# SG2000 register map
Vendor: Sophgo; File version: 1
Registers are 32-bit, read-write, reset 0x0 unless marked. A register's access mark holds for its fields unless they carry their own. Offsets are from the block's base; [hi:lo] are bit positions; lines under a group give offsets from that group; {n}, {i} and the like mark numbered series.

## UART0 — UART
Base 0x04140000
Same registers: UART1 0x04150000, UART2 0x04160000, UART3 0x04170000, UART4 0x041C0000, RTCSYS_UART 0x05022000
0x00 RBR_THR — Receive Buffer Register, Transmit Holding Register
  [7:0] RBR_THR — (R)Receive Buffer Register, Data byte received on the serial input port. (W)Transmit Holding Register, Data to be transmitted on the serial output port
0x00 DLL (alternate view of RBR_THR) — Divisor Latch Low byte Register
  [7:0] DLL — Lower 8 bits of a 16-bit Divisor Latch register that contains the baud rate divisor for the UART
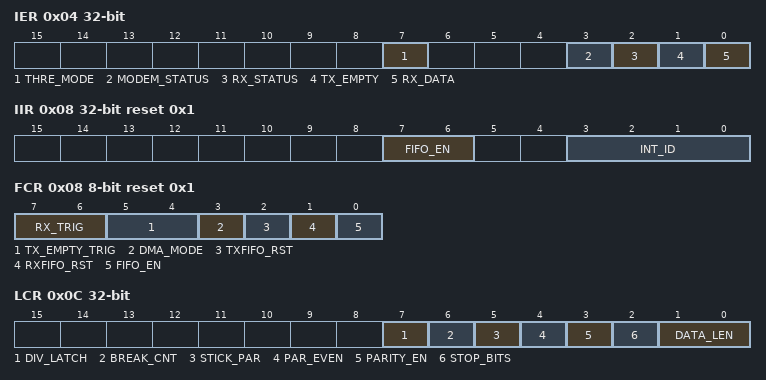
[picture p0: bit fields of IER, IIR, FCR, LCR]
0x04 IER — Interrupt Enable Register
  [7] THRE_MODE — Enable Programmable THRE Interrupt Mode
  [3] MODEM_STATUS — Enable Modem Status Interrupt
  [2] RX_STATUS — Enable Receiver Line Status Interrupt
  [1] TX_EMPTY — Enable Transmit Holding Register Empty Interrupt
  [0] RX_DATA — Enable Received Data Enable Interrupt
0x04 DLH (alternate view of IER) — Divisor Latch high byte Register
  [7:0] DLH — Upper 8-bits of a 16-bit Divisor Latch register that contains the baud rate divisor for the UART
0x08 IIR ro reset 0x1 — Interrupt Identification Register
  [7:6] FIFO_EN — FIFOs Enabled Status
    0=Disabled; 3=Enabled
  [3:0] INT_ID — Interrupt ID Status
    0=ModemStatus; 1=No interrupt pending; 2=THREmpty (Trasmit holding register empty); 4=DataAvailable (Received data available); 6=LineStatus (Receiver line status); 7=BusyDetect; 12=CharTimeout (Character Timeout)
0x08 FCR 8-bit wo reset 0x1 (alternate view of IIR) — FIFO Control Register
  [7:6] RX_TRIG — RCVR Trigger Level
    0=Char1 (1 character in FIFO); 1=Quarter (FIFO 1/4 full); 2=Half (FIFO 1/2 full); 3=FullMinus2 (FIFO 2 less than full)
  [5:4] TX_EMPTY_TRIG — TX Empty Trigger Level
    0=Empty (FIFO empty); 1=Chars2 (2 characters in FIFO); 2=Quarter (FIFO 1/4 full); 3=Half (FIFO 1/2 full)
  [3] DMA_MODE — DMA Mode Select
    0=Mode0 (Single DMA data transfers); 1=Mode1 (Multi DMA data transfers (continuous))
  [2] TXFIFO_RST — Transmit FIFO Reset
  [1] RXFIFO_RST — Receiver FIFO Reset
  [0] FIFO_EN — FIFO Enable
0x0C LCR — Line Control Register
  [7] DIV_LATCH — Divisor Latch Access Bit
  [6] BREAK_CNT — Break control bit
  [5] STICK_PAR — Stick parity
  [4] PAR_EVEN — Even parity select
  [3] PARITY_EN — Parity enable
  [2] STOP_BITS — Number of stop bits.
    0=One (One stop bit); 1=Two (Two stop bits if DATA_LEN is not 0, else 1.5 bits)
  [1:0] DATA_LEN — Data length selection
    0=Five data bits; 1=Six (Six data bits); 2=Seven data bits; 3=Eight data bits
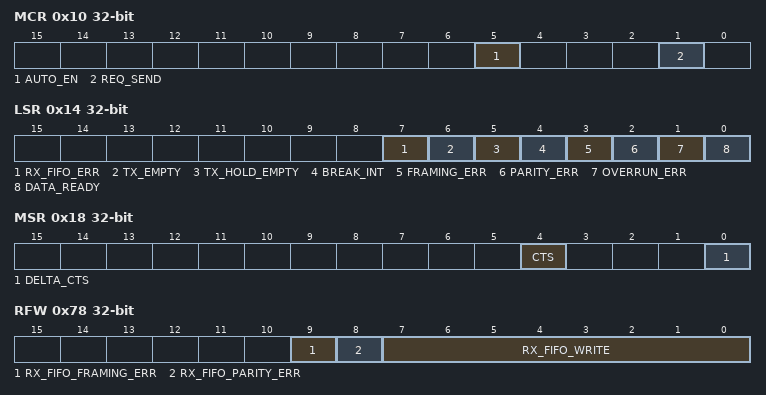
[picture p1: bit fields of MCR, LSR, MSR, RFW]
0x10 MCR access not given — Modem Control Register
  [5] AUTO_EN — Auto Flow Control Enable
  [1] REQ_SEND — Request to Send. This is used to directly control the Request to Send (rts_n) output
0x14 LSR ro reset not defined — Line Status Register
  [7] RX_FIFO_ERR — Receiver FIFO Error Bit
  [6] TX_EMPTY — Transmitter Empty Bit
  [5] TX_HOLD_EMPTY — Transmit Holding Register Empty Bit
  [4] BREAK_INT — Break Interrupt Bit
  [3] FRAMING_ERR — Framing Error Bit
  [2] PARITY_ERR — Parity Error Bit
  [1] OVERRUN_ERR — Overrun Error Bit
  [0] DATA_READY — Data Ready Bit
0x18 MSR ro reset not defined — Modem Status Register
  [4] CTS
  [0] DELTA_CTS — Delta Clear to Send.
0x20 LPDLL — Low Power Divisor Latch (Low) Register
  [7:0] ECO_DIV_LOW — Low Power Divisor Latch (Low byte) Register
0x24 LPDLH — Low Power Divisor Latch (High) Register
  [7:0] ECO_DIV_HIGH — Low Power Divisor Latch (High byte) Register
0x30 SRBR ro — Shadow Receive Buffer Register
  [7:0] RX_BUF
0x30 STHR wo reset not defined (alternate view of SRBR) — Shadow Transmit Buffer Register
  [7:0] TX_BUF — Shadow Transmit Holding Register
0x70 FAR — FIFO Access Register
  [0] FIFO_ACCESS — Used to enable a FIFO access mode for testing.
0x74 TFR — Transmit FIFO Read
  [7:0] TX_FIFO_READ — This bits are only valid when FIFO access mode is enabled.
0x78 RFW — Receive FIFO Write
  [9] RX_FIFO_FRAMING_ERR — Receive FIFO Framing Error
  [8] RX_FIFO_PARITY_ERR — Receive FIFO Parity Error
  [7:0] RX_FIFO_WRITE — Receive FIFO Write Data
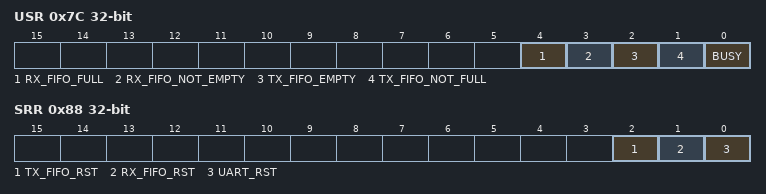
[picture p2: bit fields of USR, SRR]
0x7C USR ro reset not defined — UART Status Register
  [4] RX_FIFO_FULL — Receive FIFO Full
  [3] RX_FIFO_NOT_EMPTY — Receive FIFO Not EMPTY
  [2] TX_FIFO_EMPTY — Transmit FIFO Empty
  [1] TX_FIFO_NOT_FULL — Transmit FIFO Not Full
  [0] BUSY
0x80 TFL ro reset not defined — Transmit FIFO Level
  [5:0] TX_FIFO_LVL — This indicates the number of data entries in the transmit FIFO
0x84 RFL ro reset not defined — Receive FIFO Level
  [5:0] RX_FIFO_LVL — This indicates the number of data entries in the receive FIFO
0x88 SRR — Software Reset Register
  [2] TX_FIFO_RST — Transmitter FIFO Reset
  [1] RX_FIFO_RST — Receiver FIFO Reset
  [0] UART_RST — UART Reset
0x8C SRTS reset not defined — Shadow Request to Send
  [0] REQ_SEND — This is a shadow register for the RTS bit (MCR[1])
0x90 SBCR — Shadow Break Control Register
  [0] BREAK_CNT — This is a shadow register for the Break bit (LCR[6]).
0x94 SDMAM — Shadow DMA Mode
  [0] DMA_MODE — This is a shadow register for the DMA mode bit (FCR[3])
0x98 SFE — Shadow FIFO Enable
  [0] FIFO_EN — This is a shadow register for the FIFO enable bit (FCR[0])
0x9C SRT — Shadow RCVR Trigger
  [1:0] RX_TRIG — This is a shadow register for the RCVR trigger bits (FCR[7:6])
0xA0 STET — Shadow TX Empty Trigger
  [1:0] TX_EMPTY_TRIG — This is a shadow register for the TX empty trigger bits (FCR[5:4])
0xA4 HTX — Halt TX
  [0] HALT_TX — This register is used to halt transmissions for testing.
0xA8 DMASA — DMA Software Acknowledge
  [0] DMA_ACK — This register is used to perform a DMA software acknowledge if a transfer needs to be terminated due to an error condition.

## mailboxes
Base 0x01900000
{0x0+4i} cpu_mbox_en[{i}] (i=0..3) 8-bit — Mailbox Enable Bits
{0x10+0x10*i} cpu_mbox_int[{i}] (i=0..3) group — Interrupts Registers
  0x00 int_clr 8-bit — Interrupt Clear
  0x04 int_mask 8-bit — Interrupt Mask
  0x08 int_int 8-bit — Interrupt Status
  0x0C int_raw 8-bit — Interrupt Raw
0x60 mbox_set 8-bit
0x64 mbox_status 8-bit
{0x70+4i} cpu_mbox_status[{i}] (i=0..3) 8-bit
{0xC0+4i} spinlock[{i}] (i=0..7)
{0x400+4i} context[{i}] (i=0..15) — Data For The Messages
